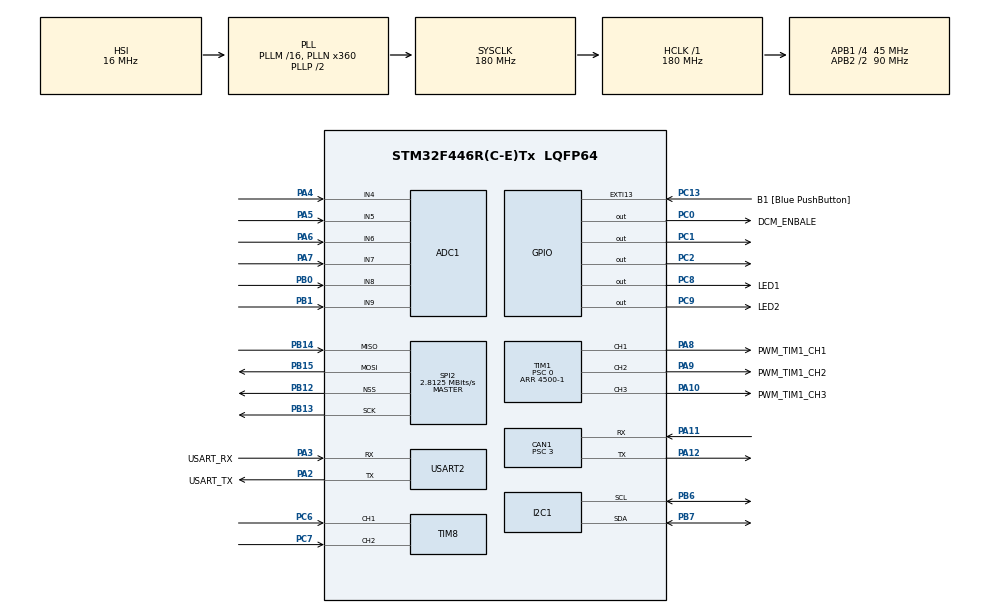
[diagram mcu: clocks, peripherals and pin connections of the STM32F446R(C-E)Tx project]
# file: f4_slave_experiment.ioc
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ADC1.Channel-0\#ChannelRegularConversion=ADC_CHANNEL_4
ADC1.Channel-1\#ChannelRegularConversion=ADC_CHANNEL_5
ADC1.Channel-2\#ChannelRegularConversion=ADC_CHANNEL_6
ADC1.Channel-3\#ChannelRegularConversion=ADC_CHANNEL_7
ADC1.Channel-4\#ChannelRegularConversion=ADC_CHANNEL_8
ADC1.Channel-6\#ChannelRegularConversion=ADC_CHANNEL_9
ADC1.ContinuousConvMode=ENABLE
ADC1.DMAContinuousRequests=ENABLE
ADC1.DiscontinuousConvMode=DISABLE
ADC1.EOCSelection=ADC_EOC_SEQ_CONV
ADC1.ExternalTrigConv=ADC_SOFTWARE_START
ADC1.NbrOfConversion=6
ADC1.NbrOfConversionFlag=1
ADC1.Rank-0\#ChannelRegularConversion=1
ADC1.Rank-1\#ChannelRegularConversion=2
ADC1.Rank-2\#ChannelRegularConversion=3
ADC1.Rank-3\#ChannelRegularConversion=4
ADC1.Rank-4\#ChannelRegularConversion=5
ADC1.Rank-6\#ChannelRegularConversion=6
ADC1.SamplingTime-0\#ChannelRegularConversion=ADC_SAMPLETIME_56CYCLES
ADC1.SamplingTime-1\#ChannelRegularConversion=ADC_SAMPLETIME_56CYCLES
ADC1.SamplingTime-2\#ChannelRegularConversion=ADC_SAMPLETIME_56CYCLES
ADC1.SamplingTime-3\#ChannelRegularConversion=ADC_SAMPLETIME_56CYCLES
ADC1.SamplingTime-4\#ChannelRegularConversion=ADC_SAMPLETIME_56CYCLES
ADC1.SamplingTime-6\#ChannelRegularConversion=ADC_SAMPLETIME_56CYCLES
ADC1.ScanConvMode=ENABLE
ADC1.master=1
CAN1.AWUM=DISABLE
CAN1.BS1=CAN_BS1_12TQ
CAN1.BS2=CAN_BS2_2TQ
CAN1.CalculateBaudRate=1000000
CAN1.CalculateTimeBit=1000
CAN1.CalculateTimeQuantum=66.66666666666666
CAN1.Prescaler=3
Dma.ADC1.0.Direction=DMA_PERIPH_TO_MEMORY
Dma.ADC1.0.FIFOMode=DMA_FIFOMODE_DISABLE
Dma.ADC1.0.Instance=DMA2_Stream4
Dma.ADC1.0.MemDataAlignment=DMA_MDATAALIGN_HALFWORD
Dma.ADC1.0.MemInc=DMA_MINC_ENABLE
Dma.ADC1.0.Mode=DMA_CIRCULAR
Dma.ADC1.0.PeriphDataAlignment=DMA_PDATAALIGN_HALFWORD
Dma.ADC1.0.PeriphInc=DMA_PINC_DISABLE
Dma.ADC1.0.Priority=DMA_PRIORITY_MEDIUM
Dma.Request0=ADC1
Mcu.Family=STM32F4
Mcu.Name=STM32F446R(C-E)Tx
Mcu.Package=LQFP64
NVIC.ADC_IRQn=true\:0\:0\:false\:false\:true\:true\:true\:true
NVIC.CAN1_RX0_IRQn=true\:0\:0\:false\:false\:true\:true\:true\:true
NVIC.CAN1_RX1_IRQn=true\:0\:0\:false\:false\:true\:true\:true\:true
NVIC.CAN1_TX_IRQn=true\:0\:0\:false\:false\:true\:true\:true\:true
NVIC.DMA2_Stream4_IRQn=true\:0\:0\:false\:false\:true\:false\:true\:true
NVIC.PriorityGroup=NVIC_PRIORITYGROUP_0
NVIC.TIM2_IRQn=true\:0\:0\:false\:false\:true\:true\:true\:true
NVIC.TIM8_TRG_COM_TIM14_IRQn=true\:0\:0\:false\:false\:true\:true\:true\:true
NVIC.TIM8_UP_TIM13_IRQn=true\:0\:0\:false\:false\:true\:true\:true\:true
PA10.GPIO_Label=PWM_TIM1_CH3
PA10.Signal=S_TIM1_CH3
PA11.Mode=CAN_Activate
PA11.Signal=CAN1_RX
PA12.Mode=CAN_Activate
PA12.Signal=CAN1_TX
PA13.GPIO_Label=TMS
PA13.Mode=JTAG_5_pins
PA13.Signal=SYS_JTMS-SWDIO
PA14.GPIO_Label=TCK
PA14.Mode=JTAG_5_pins
PA14.Signal=SYS_JTCK-SWCLK
PA15.Mode=JTAG_5_pins
PA15.Signal=SYS_JTDI
PA2.GPIO_Label=USART_TX
PA2.Mode=Asynchronous
PA2.Signal=USART2_TX
PA3.GPIO_Label=USART_RX
PA3.Mode=Asynchronous
PA3.Signal=USART2_RX
PA4.Signal=ADCx_IN4
PA5.Signal=ADCx_IN5
PA6.Signal=ADCx_IN6
PA7.Signal=ADCx_IN7
PA8.GPIO_Label=PWM_TIM1_CH1
PA8.Signal=S_TIM1_CH1
PA9.GPIO_Label=PWM_TIM1_CH2
PA9.Signal=S_TIM1_CH2
PB0.Signal=ADCx_IN8
PB1.Signal=ADCx_IN9
PB12.Mode=NSS_Signal_Hard_Output
PB12.Signal=SPI2_NSS
PB13.Mode=Full_Duplex_Master
PB13.Signal=SPI2_SCK
PB14.Mode=Full_Duplex_Master
PB14.Signal=SPI2_MISO
PB15.Mode=Full_Duplex_Master
PB15.Signal=SPI2_MOSI
PB3.GPIO_Label=SWO
PB3.Mode=JTAG_5_pins
PB3.Signal=SYS_JTDO-SWO
PB4.Mode=JTAG_5_pins
PB4.Signal=SYS_JTRST
PB6.Mode=I2C
PB6.Signal=I2C1_SCL
PB7.Mode=I2C
PB7.Signal=I2C1_SDA
PC0.GPIO_Label=DCM_ENBALE
PC0.Signal=GPIO_Output
PC1.Signal=GPIO_Output
PC13.GPIO_Label=B1 [Blue PushButton]
PC13.GPIO_ModeDefaultEXTI=GPIO_MODE_IT_FALLING
PC13.Signal=GPXTI13
PC2.Signal=GPIO_Output
PC6.Signal=S_TIM8_CH1
PC7.Signal=S_TIM8_CH2
PC8.GPIO_Label=LED1
PC8.Signal=GPIO_Output
PC9.GPIO_Label=LED2
PC9.Signal=GPIO_Output
PH0-OSC_IN.Mode=HSE-External-Oscillator
PH0-OSC_IN.Signal=RCC_OSC_IN
PH1-OSC_OUT.Mode=HSE-External-Oscillator
PH1-OSC_OUT.Signal=RCC_OSC_OUT
ProjectManager.HeapSize=0x200
ProjectManager.StackSize=0x400
ProjectManager.TargetToolchain=STM32CubeIDE
RCC.48MHZClocksFreq_Value=84000000
RCC.AHBFreq_Value=180000000
RCC.APB1CLKDivider=RCC_HCLK_DIV4
RCC.APB1Freq_Value=45000000
RCC.APB1TimFreq_Value=90000000
RCC.APB2CLKDivider=RCC_HCLK_DIV2
RCC.APB2Freq_Value=90000000
RCC.APB2TimFreq_Value=180000000
RCC.CortexFreq_Value=180000000
RCC.FLatency-AdvancedSettings=FLASH_LATENCY_5
RCC.HCLKFreq_Value=180000000
RCC.HSE_VALUE=8000000
RCC.HSI_VALUE=16000000
RCC.PLLN=360
RCC.SYSCLKFreq_VALUE=180000000
RCC.SYSCLKSource=RCC_SYSCLKSOURCE_PLLCLK
RCC.USBFreq_Value=180000000
RCC.VCOOutputFreq_Value=360000000
SH.ADCx_IN4.0=ADC1_IN4,IN4
SH.ADCx_IN5.0=ADC1_IN5,IN5
SH.ADCx_IN6.0=ADC1_IN6,IN6
SH.ADCx_IN7.0=ADC1_IN7,IN7
SH.ADCx_IN8.0=ADC1_IN8,IN8
SH.ADCx_IN9.0=ADC1_IN9,IN9
SH.S_TIM1_CH1.0=TIM1_CH1,PWM Generation1 CH1
SH.S_TIM1_CH2.0=TIM1_CH2,PWM Generation2 CH2
SH.S_TIM1_CH3.0=TIM1_CH3,PWM Generation3 CH3
SH.S_TIM8_CH1.0=TIM8_CH1,Encoder_Interface
SH.S_TIM8_CH2.0=TIM8_CH2,Encoder_Interface
SPI2.BaudRatePrescaler=SPI_BAUDRATEPRESCALER_16
SPI2.CalculateBaudRate=2.8125 MBits/s
SPI2.Direction=SPI_DIRECTION_2LINES
SPI2.Mode=SPI_MODE_MASTER
SPI2.VirtualNSS=VM_NSSHARD
SPI2.VirtualType=VM_MASTER
TIM1.AutoReloadPreload=TIM_AUTORELOAD_PRELOAD_ENABLE
TIM1.Channel-PWM\ Generation1\ CH1=TIM_CHANNEL_1
TIM1.Channel-PWM\ Generation2\ CH2=TIM_CHANNEL_2
TIM1.Channel-PWM\ Generation3\ CH3=TIM_CHANNEL_3
TIM1.Period=4500-1
TIM1.Prescaler=0
TIM13.Period=2000-1
TIM13.Prescaler=45000-1
TIM2.AutoReloadPreload=TIM_AUTORELOAD_PRELOAD_DISABLE
TIM2.Period=4500-1
TIM2.TIM_MasterOutputTrigger=TIM_TRGO_RESET
TIM8.EncoderMode=TIM_ENCODERMODE_TI12
USART2.VirtualMode=VM_ASYNC
VP_TIM13_VS_ClockSourceINT.Mode=Enable_Timer
VP_TIM1_VS_ClockSourceINT.Mode=Internal
VP_TIM1_VS_ClockSourceITR.Mode=TriggerSource_ITR0
VP_TIM1_VS_ControllerModeReset.Mode=Reset Mode
VP_TIM2_VS_ClockSourceINT.Mode=Internal
VP_TIM2_VS_ClockSourceITR.Mode=TriggerSource_ITR0
VP_TIM2_VS_ControllerModeReset.Mode=Reset Mode
board=NUCLEO-F446RE

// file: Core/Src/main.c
/* USER CODE BEGIN Header */
/**
  ******************************************************************************
  * @file           : main.c
  * @brief          : Main program body
  ******************************************************************************
  * @attention
  *
  * Copyright (c) 2024 STMicroelectronics.
  * All rights reserved.
  *
  * This software is licensed under terms that can be found in the LICENSE file
  * in the root directory of this software component.
  * If no LICENSE file comes with this software, it is provided AS-IS.
  *
  ******************************************************************************
  */
/* USER CODE END Header */
#include "main.h"
#include "adc.h"
#include "can.h"
#include "dma.h"
#include "i2c.h"
#include "spi.h"
#include "tim.h"
#include "usart.h"
#include "gpio.h"

/* USER CODE BEGIN Includes */
#include "user_header/user_main.h"
/* USER CODE END Includes */

void SystemClock_Config(void);

int main(void)
{

  /* MCU Configuration--------------------------------------------------------*/

  /* Reset of all peripherals, Initializes the Flash interface and the Systick. */
  HAL_Init();

  /* Configure the system clock */
  SystemClock_Config();

  /* Initialize all configured peripherals */
  MX_GPIO_Init();
  MX_CAN1_Init();
  MX_USART2_UART_Init();
  MX_DMA_Init();
  MX_ADC1_Init();
  MX_SPI2_Init();
  MX_TIM1_Init();
//  MX_DMA_Init();
  MX_I2C1_Init();
  MX_TIM13_Init();
  MX_TIM8_Init();
  MX_TIM2_Init();
  /* USER CODE BEGIN 2 */
  user_initialize();
  /* USER CODE END 2 */

  /* Infinite loop */
  /* USER CODE BEGIN WHILE */
  while (1)
  {
	  user_loop();
    /* USER CODE END WHILE */

  }
}

void SystemClock_Config(void)
{
  RCC_OscInitTypeDef RCC_OscInitStruct = {0};
  RCC_ClkInitTypeDef RCC_ClkInitStruct = {0};

  /** Configure the main internal regulator output voltage
  */
  __HAL_RCC_PWR_CLK_ENABLE();
  __HAL_PWR_VOLTAGESCALING_CONFIG(PWR_REGULATOR_VOLTAGE_SCALE1);

  /** Initializes the RCC Oscillators according to the specified parameters
  * in the RCC_OscInitTypeDef structure.
  */
  RCC_OscInitStruct.OscillatorType = RCC_OSCILLATORTYPE_HSI;
  RCC_OscInitStruct.HSIState = RCC_HSI_ON;
  RCC_OscInitStruct.HSICalibrationValue = RCC_HSICALIBRATION_DEFAULT;
  RCC_OscInitStruct.PLL.PLLState = RCC_PLL_ON;
  RCC_OscInitStruct.PLL.PLLSource = RCC_PLLSOURCE_HSI;
  RCC_OscInitStruct.PLL.PLLM = 16;
  RCC_OscInitStruct.PLL.PLLN = 360;
  RCC_OscInitStruct.PLL.PLLP = RCC_PLLP_DIV2;
  RCC_OscInitStruct.PLL.PLLQ = 2;
  RCC_OscInitStruct.PLL.PLLR = 2;
  if (HAL_RCC_OscConfig(&RCC_OscInitStruct) != HAL_OK)
  {
    Error_Handler();
  }

  /** Activate the Over-Drive mode
  */
  if (HAL_PWREx_EnableOverDrive() != HAL_OK)
  {
    Error_Handler();
  }

  /** Initializes the CPU, AHB and APB buses clocks
  */
  RCC_ClkInitStruct.ClockType = RCC_CLOCKTYPE_HCLK|RCC_CLOCKTYPE_SYSCLK
                              |RCC_CLOCKTYPE_PCLK1|RCC_CLOCKTYPE_PCLK2;
  RCC_ClkInitStruct.SYSCLKSource = RCC_SYSCLKSOURCE_PLLCLK;
  RCC_ClkInitStruct.AHBCLKDivider = RCC_SYSCLK_DIV1;
  RCC_ClkInitStruct.APB1CLKDivider = RCC_HCLK_DIV4;
  RCC_ClkInitStruct.APB2CLKDivider = RCC_HCLK_DIV2;

  if (HAL_RCC_ClockConfig(&RCC_ClkInitStruct, FLASH_LATENCY_5) != HAL_OK)
  {
    Error_Handler();
  }
}

void Error_Handler(void)
{
  __disable_irq();
  while (1)
  {
  }
}
